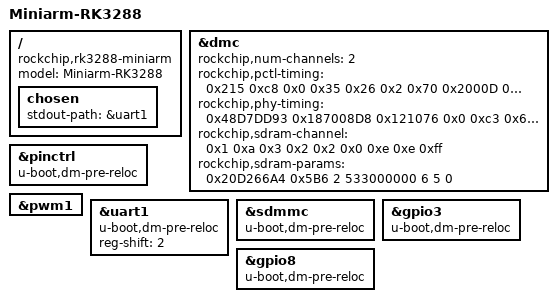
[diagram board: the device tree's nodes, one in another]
/*
 * (C) Copyright 2016 Rockchip Electronics Co., Ltd
 *
 * SPDX-License-Identifier:     GPL-2.0+ X11
 */

/dts-v1/;
#include "rk3288-miniarm.dtsi"

/ {
	model = "Miniarm-RK3288";
	compatible = "rockchip,rk3288-miniarm", "rockchip,rk3288";

	chosen {
		stdout-path = &uart1;
	};
};

//1GB

&dmc {
	rockchip,num-channels = <2>;

	rockchip,pctl-timing = <0x215 0xc8 0x0 0x35 0x26 0x2 0x70 0x2000D
		0x6 0x0 0x8 0x4 0x17 0x24 0xd 0x6
		0x4 0x8 0x4 0x76 0x4 0x0 0x30 0x0
		0x1 0x2 0x2 0x4 0x0 0x0 0xc0 0x4
		0x8 0x1f4>;
	rockchip,phy-timing = <0x48D7DD93 0x187008D8 0x121076
		0x0 0xc3 0x6 0x1>;
	rockchip,sdram-channel = /bits/ 8 <0x1 0xa 0x3 0x2 0x2 0x0 0xe 0xe 0xff>;
	rockchip,sdram-params = <0x20D266A4 0x5B6 2 533000000 6 5 0>;
};

//2GB
/*
&dmc {
	rockchip,num-channels = <2>;
	rockchip,pctl-timing = <0x215 0xc8 0x0 0x35 0x26 0x2 0x70 0x2000D
		0x6 0x0 0x8 0x4 0x17 0x24 0xd 0x6
		0x4 0x8 0x4 0x76 0x4 0x0 0x30 0x0
		0x1 0x2 0x2 0x4 0x0 0x0 0xc0 0x4
		0x8 0x1f4>;
	rockchip,phy-timing = <0x48D7DD93 0x187008D8 0x121076
		0x0 0xc3 0x6 0x2>;
	rockchip,sdram-channel = /bits/ 8 <0x1 0xa 0x3 0x2 0x2 0x0 0xf 0xf 0xff>;
	rockchip,sdram-params = <0x20D266A4 0x5B6 14 533000000 6 9 1>;
};
*/

//4GB
/*
&dmc {
	rockchip,num-channels = <2>;

	rockchip,pctl-timing = <0x215 0xc8 0x0 0x35 0x26 0x2 0x70 0x2000D
		0x6 0x0 0x8 0x4 0x17 0x24 0xd 0x6
		0x4 0x8 0x4 0x76 0x4 0x0 0x30 0x0
		0x1 0x2 0x2 0x4 0x0 0x0 0xc0 0x4
		0x8 0x1f4>;
	rockchip,phy-timing = <0x48D7DD93 0x187008D8 0x121076
		0x0 0xc3 0x6 0x2>;
	rockchip,sdram-channel = /bits/ 8 <0x2 0xb 0x3 0x2 0x2 0x0 0xe 0xe 0xff>;
	rockchip,sdram-params = <0x20D266A4 0x5B6 14 533000000 6 13 1>;
};
*/



&pinctrl {
	u-boot,dm-pre-reloc;
};

&pwm1 {
	status = "okay";
};

&uart1 {
	u-boot,dm-pre-reloc;
	reg-shift = <2>;
};

&sdmmc {
	u-boot,dm-pre-reloc;
};

&gpio3 {
	u-boot,dm-pre-reloc;
};

&gpio8 {
	u-boot,dm-pre-reloc;
};
